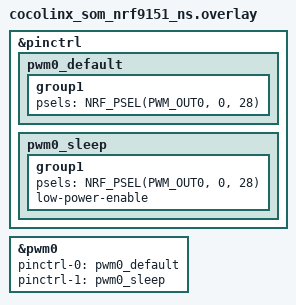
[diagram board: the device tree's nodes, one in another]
/*
 * Copyright (c) 2024 Nordic Semiconductor ASA
 *
 * SPDX-License-Identifier: LicenseRef-Nordic-5-Clause
 */

#include <samples/cellular/nrf91_no_bootloader_partitions.dtsi>
#include <samples/cellular/nrf91_sram_partitions.dtsi>

&pinctrl {
	pwm0_default: pwm0_default {
		group1 {
			psels = <NRF_PSEL(PWM_OUT0, 0, 28)>;
		};
	};

	pwm0_sleep: pwm0_sleep {
		group1 {
			psels = <NRF_PSEL(PWM_OUT0, 0, 28)>;
			low-power-enable;
		};
	};
};

&pwm0 {
	status = "okay";
	pinctrl-0 = <&pwm0_default>;
	pinctrl-1 = <&pwm0_sleep>;
	pinctrl-names = "default", "sleep";
};
